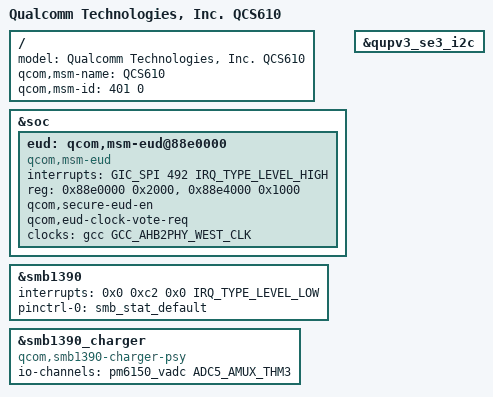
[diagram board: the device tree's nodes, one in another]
// SPDX-License-Identifier: BSD-3-Clause
/*
 * Copyright (c) 2025 Qualcomm Innovation Center, Inc. All rights reserved.
 */

#include "sm6150.dtsi"
#include "sm6150-pmic-overlay.dtsi"

/ {
	model = "Qualcomm Technologies, Inc. QCS610";
	qcom,msm-name = "QCS610";
	qcom,msm-id = <401 0>;
};

&soc {
	eud: qcom,msm-eud@88e0000 {
		compatible = "qcom,msm-eud";
		interrupt-names = "eud_irq";
		interrupts = <GIC_SPI 492 IRQ_TYPE_LEVEL_HIGH>;
		reg = <0x88e0000 0x2000>,
		      <0x88e4000 0x1000>;
		reg-names = "eud_base", "eud_mode_mgr2";
		qcom,secure-eud-en;
		qcom,eud-clock-vote-req;
		clocks = <&gcc GCC_AHB2PHY_WEST_CLK>;
		clock-names = "eud_ahb2phy_clk";
		status = "ok";
	};
};

&qupv3_se3_i2c {
	status = "ok";
	#include "smb1390.dtsi"
};

&smb1390 {
	/delete-property/ interrupts;
	interrupts = <0x0 0xc2 0x0 IRQ_TYPE_LEVEL_LOW>;
	pinctrl-names = "default";
	pinctrl-0 = <&smb_stat_default>;
	status = "ok";
};

&smb1390_charger {
	/delete-property/ compatible;
	compatible = "qcom,smb1390-charger-psy";
	io-channels = <&pm6150_vadc ADC5_AMUX_THM3>;
	io-channel-names = "cp_die_temp";
	status = "ok";
};
